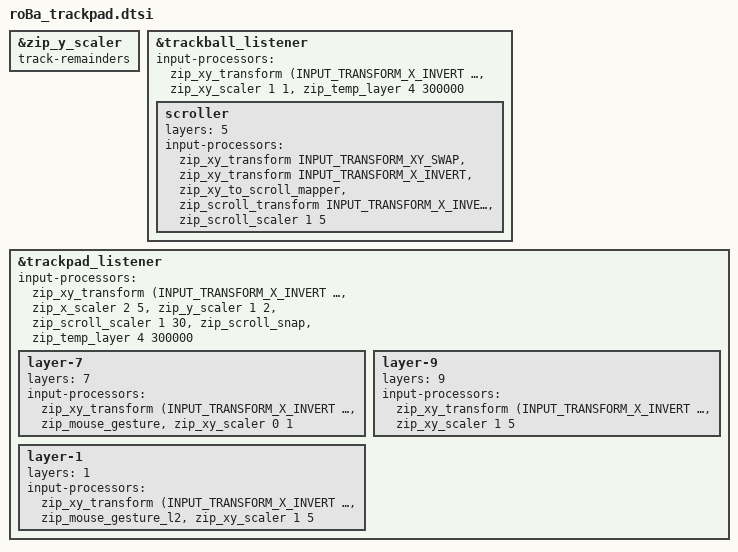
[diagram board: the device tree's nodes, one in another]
#include <input/processors.dtsi>
#include <dt-bindings/zmk/input_transform.h>
#include <mouse-gesture.dtsi>
#include <scroll-snap.dtsi>

&zip_y_scaler { track-remainders; };

&trackball_listener {
    // 右手トラックボール（カーソル・スクロール）
    input-processors = <&zip_xy_transform (INPUT_TRANSFORM_X_INVERT | INPUT_TRANSFORM_Y_INVERT)>, <&zip_xy_scaler 1 1>, <&zip_temp_layer 4 300000>;

    scroller {
        layers = <5>;  // レイヤー5でスクロールモード
        input-processors = <&zip_xy_transform INPUT_TRANSFORM_XY_SWAP>, <&zip_xy_transform INPUT_TRANSFORM_X_INVERT>, <&zip_xy_to_scroll_mapper>, <&zip_scroll_transform INPUT_TRANSFORM_X_INVERT>, <&zip_scroll_scaler 1 5>;
    };
};

&trackpad_listener {
    // 左手トラックパッド（カーソル・ジェスチャー・ネイティブスクロール）
    // XY反転 → スケール（Y補正） → スクロール減速 → スクロールスナップ → オートマウスレイヤー4に自動切替
    input-processors = <&zip_xy_transform (INPUT_TRANSFORM_X_INVERT | INPUT_TRANSFORM_Y_INVERT)>, <&zip_x_scaler 2 5>, <&zip_y_scaler 1 2>, <&zip_scroll_scaler 1 30>, <&zip_scroll_snap>, <&zip_temp_layer 4 300000>;

    layer-7 {
        layers = <7>;
        input-processors = <&zip_xy_transform (INPUT_TRANSFORM_X_INVERT | INPUT_TRANSFORM_Y_INVERT)>, <&zip_mouse_gesture>, <&zip_xy_scaler 0 1>;
    };

    layer-9 {
        layers = <9>;
        input-processors = <&zip_xy_transform (INPUT_TRANSFORM_X_INVERT | INPUT_TRANSFORM_Y_INVERT)>, <&zip_xy_scaler 1 5>;
    };

    layer-1 {
        layers = <1>;
        input-processors = <&zip_xy_transform (INPUT_TRANSFORM_X_INVERT | INPUT_TRANSFORM_Y_INVERT)>, <&zip_mouse_gesture_l2>, <&zip_xy_scaler 1 5>;
    };
};
